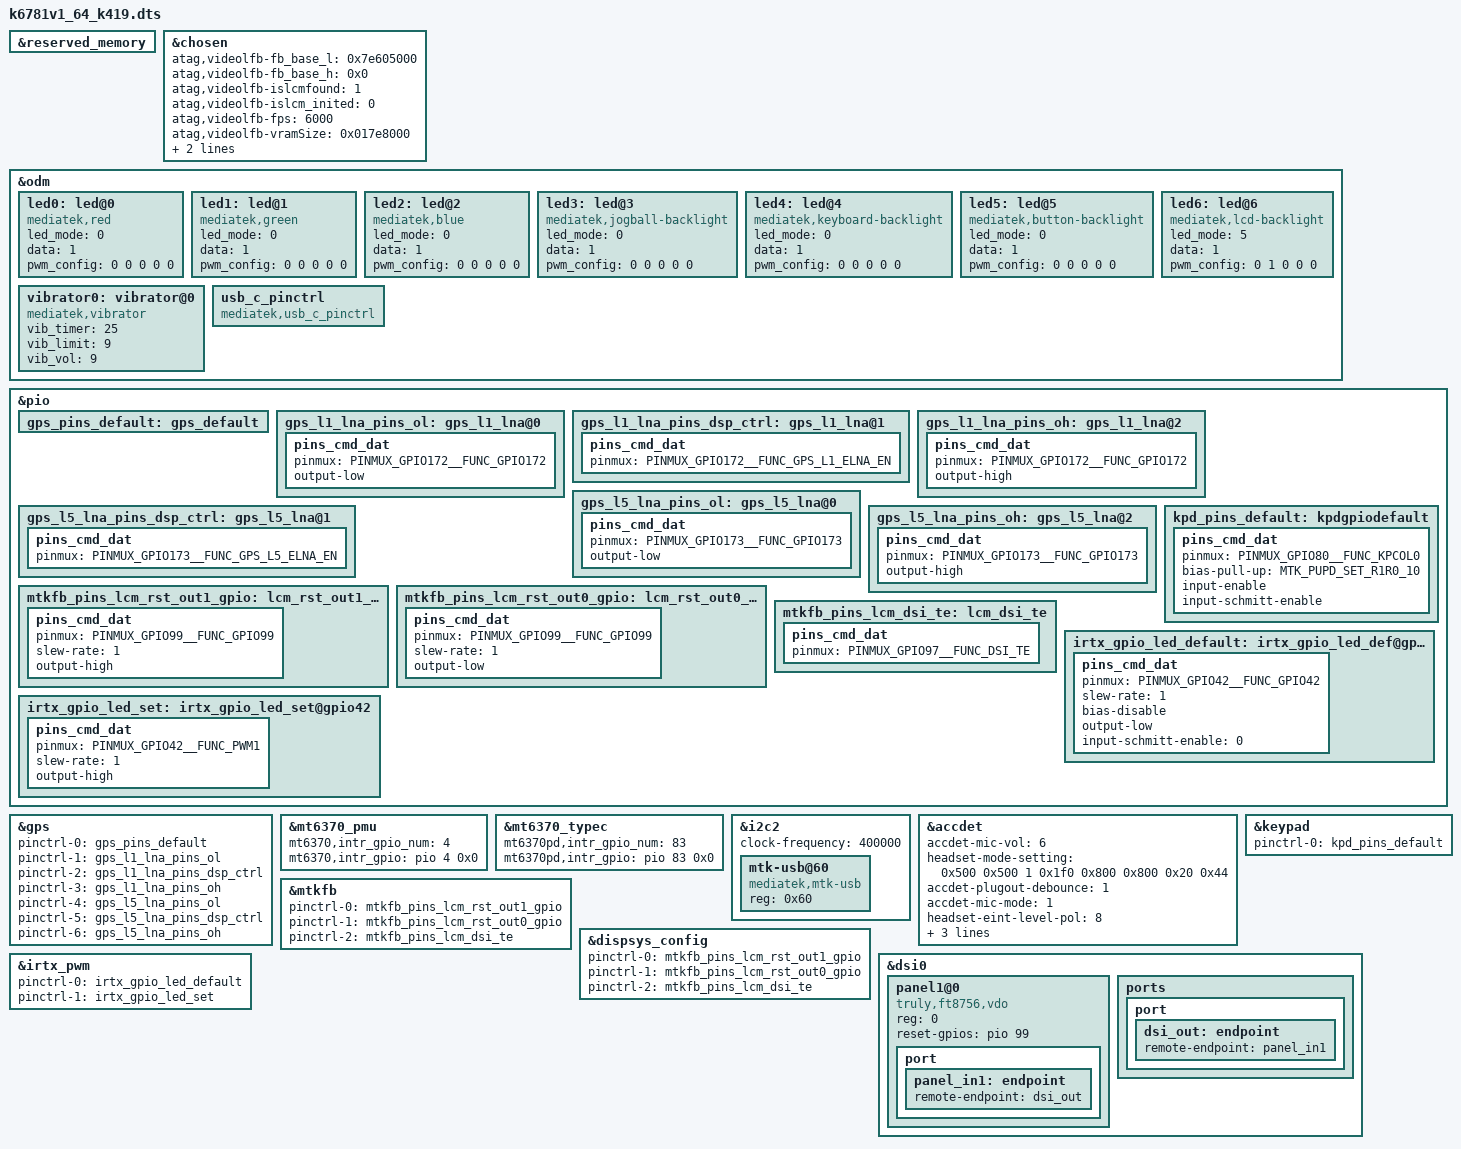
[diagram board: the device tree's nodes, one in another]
// SPDX-License-Identifier: GPL-2.0+
/*
 * Copyright (C) 2016 MediaTek Inc.
 */

/dts-v1/;
/plugin/;
#include <dt-bindings/interrupt-controller/irq.h>
#include <dt-bindings/interrupt-controller/arm-gic.h>
#include <dt-bindings/pinctrl/mt6781-pinfunc.h>

&reserved_memory {
};

/* chosen */
&chosen {
	/* fpga may has no lk, we need to specify display info here */
	/* fb buffer is reserved using this dts by memory node above */
	atag,videolfb-fb_base_l = <0x7e605000>;
	atag,videolfb-fb_base_h = <0x0>;
	atag,videolfb-islcmfound = <1>;
	atag,videolfb-islcm_inited = <0>;
	atag,videolfb-fps= <6000>;
	atag,videolfb-vramSize= <0x017e8000>;
	atag,videolfb-lcmname=
		"nt35695_fhd_dsi_cmd_truly_rt5081_drv";
};

&odm {
	led0:led@0 {
		compatible = "mediatek,red";
		led_mode = <0>;
		data = <1>;
		pwm_config = <0 0 0 0 0>;
	};
	led1:led@1 {
		compatible = "mediatek,green";
		led_mode = <0>;
		data = <1>;
		pwm_config = <0 0 0 0 0>;
	};
	led2:led@2 {
		compatible = "mediatek,blue";
		led_mode = <0>;
		data = <1>;
		pwm_config = <0 0 0 0 0>;
	};
	led3:led@3 {
		compatible = "mediatek,jogball-backlight";
		led_mode = <0>;
		data = <1>;
		pwm_config = <0 0 0 0 0>;
	};
	led4:led@4 {
		compatible = "mediatek,keyboard-backlight";
		led_mode = <0>;
		data = <1>;
		pwm_config = <0 0 0 0 0>;
	};
	led5:led@5 {
		compatible = "mediatek,button-backlight";
		led_mode = <0>;
		data = <1>;
		pwm_config = <0 0 0 0 0>;
	};
	led6:led@6 {
		compatible = "mediatek,lcd-backlight";
		led_mode = <5>;
		data = <1>;
		pwm_config = <0 1 0 0 0>;
	};
	vibrator0:vibrator@0 {
		compatible = "mediatek,vibrator";
		vib_timer = <25>;
		vib_limit = <9>;
		vib_vol= <9>;
	};

	usb_c_pinctrl:usb_c_pinctrl {
		compatible = "mediatek,usb_c_pinctrl";
	};
};

/* GPS GPIO standardization start */
&pio {
	gps_pins_default: gps_default {
	};

	gps_l1_lna_pins_ol: gps_l1_lna@0 {
		pins_cmd_dat {
			pinmux = <PINMUX_GPIO172__FUNC_GPIO172>;
			output-low;
		};
	};
	gps_l1_lna_pins_dsp_ctrl: gps_l1_lna@1 {
		pins_cmd_dat {
			pinmux = <PINMUX_GPIO172__FUNC_GPS_L1_ELNA_EN>;
		};
	};
	gps_l1_lna_pins_oh: gps_l1_lna@2 {
		pins_cmd_dat {
			pinmux = <PINMUX_GPIO172__FUNC_GPIO172>;
			output-high;
		};
	};

	gps_l5_lna_pins_ol: gps_l5_lna@0 {
		pins_cmd_dat {
			pinmux = <PINMUX_GPIO173__FUNC_GPIO173>;
			output-low;
		};
	};
	gps_l5_lna_pins_dsp_ctrl: gps_l5_lna@1 {
		pins_cmd_dat {
			pinmux = <PINMUX_GPIO173__FUNC_GPS_L5_ELNA_EN>;
		};
	};
	gps_l5_lna_pins_oh: gps_l5_lna@2 {
		pins_cmd_dat {
			pinmux = <PINMUX_GPIO173__FUNC_GPIO173>;
			output-high;
		};
	};
};

&gps {
	pinctrl-names = "default",
		"gps_l1_lna_disable",
		"gps_l1_lna_dsp_ctrl",
		"gps_l1_lna_enable",
		"gps_l5_lna_disable",
		"gps_l5_lna_dsp_ctrl",
		"gps_l5_lna_enable";
	pinctrl-0 = <&gps_pins_default>;
	pinctrl-1 = <&gps_l1_lna_pins_ol>;
	pinctrl-2 = <&gps_l1_lna_pins_dsp_ctrl>;
	pinctrl-3 = <&gps_l1_lna_pins_oh>;
	pinctrl-4 = <&gps_l5_lna_pins_ol>;
	pinctrl-5 = <&gps_l5_lna_pins_dsp_ctrl>;
	pinctrl-6 = <&gps_l5_lna_pins_oh>;
	status = "okay";
};
/* GPS GPIO standardization end */

&mt6370_pmu {
	mt6370,intr_gpio_num = <4>; /* direct defined GPIO num */
	mt6370,intr_gpio = <&pio 4 0x0>;
};

&mt6370_typec {
	mt6370pd,intr_gpio_num = <83>; /* direct defined GPIO num */
	mt6370pd,intr_gpio = <&pio 83 0x0>;
};

&i2c2 {
	clock-frequency = <400000>;
	mtk-usb@60 {
		compatible = "mediatek,mtk-usb";
		reg = <0x60>;
		status = "okay";
	};
};

/* accdet start */
&accdet {
	/* accdet micbias voltage: 0x07,2.7v;0x05,2.5v;0x02,1.9v */
	accdet-mic-vol = <6>;
	headset-mode-setting = <0x500 0x500 1 0x1f0 0x800 0x800 0x20 0x44>;
	accdet-plugout-debounce = <1>;
	/*1:ACC mode, 2:low cost without in bias, 6:low cost with in bias*/
	accdet-mic-mode = <1>;
	/* eint_level_trigger: 8,LEVEL_LOW(DEF) ;4,LV_HIGH;others,LV_LOW */
	headset-eint-level-pol = <8>;
	/*0--MD_MAX--UP_MAX--DW_MAX*/
	headset-three-key-threshold = <0 80 220 400>;
	headset-three-key-threshold-CDD = <0 121 192 600>;
	/*0--MD_MAX--VOICE_MAX--UP_MAX--DW_MAX*/
	headset-four-key-threshold = <0 58 121 192 400>;
	status = "okay";
};
/* accdet end */

/* keypad start */
&keypad {
	pinctrl-names = "default";
	pinctrl-0 = <&kpd_pins_default>;
};

&pio {
	kpd_pins_default: kpdgpiodefault {
		pins_cmd_dat {
			pinmux = <PINMUX_GPIO80__FUNC_KPCOL0>;
			bias-pull-up = <MTK_PUPD_SET_R1R0_10>;
			input-enable;
			input-schmitt-enable;
		};
	};
};
/* keypad end */

#ifndef CONFIG_FPGA_EARLY_PORTING
&pio {
	mtkfb_pins_lcm_rst_out1_gpio: lcm_rst_out1_gpio {
		pins_cmd_dat {
			pinmux = <PINMUX_GPIO99__FUNC_GPIO99>;
			slew-rate = <1>;
			output-high;
		};
	};

	mtkfb_pins_lcm_rst_out0_gpio: lcm_rst_out0_gpio {
		pins_cmd_dat {
			pinmux = <PINMUX_GPIO99__FUNC_GPIO99>;
			slew-rate = <1>;
			output-low;
		};
	};
	mtkfb_pins_lcm_dsi_te: lcm_dsi_te {
		pins_cmd_dat {
			pinmux = <PINMUX_GPIO97__FUNC_DSI_TE>;
		};
	};
};

&mtkfb {
	pinctrl-names = "lcm_rst_out1_gpio", "lcm_rst_out0_gpio",
		"mode_te_te";
	pinctrl-0 = <&mtkfb_pins_lcm_rst_out1_gpio>;
	pinctrl-1 = <&mtkfb_pins_lcm_rst_out0_gpio>;
	pinctrl-2 = <&mtkfb_pins_lcm_dsi_te>;
	status = "okay";
};

&dispsys_config {
	pinctrl-names =
		"lcm_rst_out1_gpio", "lcm_rst_out0_gpio",
		"mode_te_te";
	pinctrl-0 = <&mtkfb_pins_lcm_rst_out1_gpio>;
	pinctrl-1 = <&mtkfb_pins_lcm_rst_out0_gpio>;
	pinctrl-2 = <&mtkfb_pins_lcm_dsi_te>;
	status = "okay";
};

&dsi0 {
	status = "okay";
	#address-cells = <1>;
	#size-cells = <0>;
	panel1@0 {
		compatible = "truly,ft8756,vdo";
		reg = <0>;
		reset-gpios = <&pio 99 0>;
		pinctrl-names = "default";
		port {
			panel_in1: endpoint {
				remote-endpoint = <&dsi_out>;
			};
		};
	};
	ports {
		port {
			dsi_out: endpoint {
				remote-endpoint = <&panel_in1>;
			};
		};
	};
};

/* IRTX GPIO Start */
&irtx_pwm {
	pinctrl-names = "irtx_gpio_led_default", "irtx_gpio_led_set";
	pinctrl-0 = <&irtx_gpio_led_default>;
	pinctrl-1 = <&irtx_gpio_led_set>;
	status = "okay";
};
&pio {
	/* IRTX GPIO Settings -Start */
	/* default: GPIO0, output, high */
	irtx_gpio_led_default:irtx_gpio_led_def@gpio42 {
		pins_cmd_dat {
			pinmux = <PINMUX_GPIO42__FUNC_GPIO42>;
			slew-rate = <1>;
			bias-disable;
			output-low;
			input-schmitt-enable = <0>;
		};
	};

	irtx_gpio_led_set:irtx_gpio_led_set@gpio42 {
		pins_cmd_dat {
			pinmux = <PINMUX_GPIO42__FUNC_PWM1>;
			slew-rate = <1>;
			output-high;
		};
	};
}; /* IRTX GPIO Settings -End */

#endif


#include <k6781v1_64_k419/cust.dtsi>
#include "mediatek/cust_mt6781_camera.dtsi"
#include "mediatek/cust_mt6781_touch_1080x2300.dtsi"
/*End of this file, DO NOT ADD ANYTHING HERE*/
